AUTOSAR XML (schema 00048)
package /HuaweiMDC/FunctionalSoftware/RoadFeatureApplication/Execution
  executable RoadFeatureExecutable
    root sw component prototype RoadFeatureRootSwComponent: application-type=RoadFeatureApplicationSwComponent
package /HuaweiMDC/FunctionalSoftware/RoadFeatureApplication/SwComponent
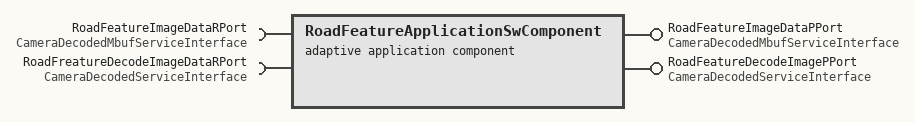
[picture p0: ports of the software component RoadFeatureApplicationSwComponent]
  adaptive application sw component type RoadFeatureApplicationSwComponent
    require port RoadFeatureImageDataRPort: required-interface=CameraDecodedMbufServiceInterface
    provide port RoadFeatureImageDataPPort: provided-interface=CameraDecodedMbufServiceInterface
    require port RoadFreatureDecodeImageDataRPort: required-interface=CameraDecodedServiceInterface
    provide port RoadFeatureDecodeImagePPort: provided-interface=CameraDecodedServiceInterface
